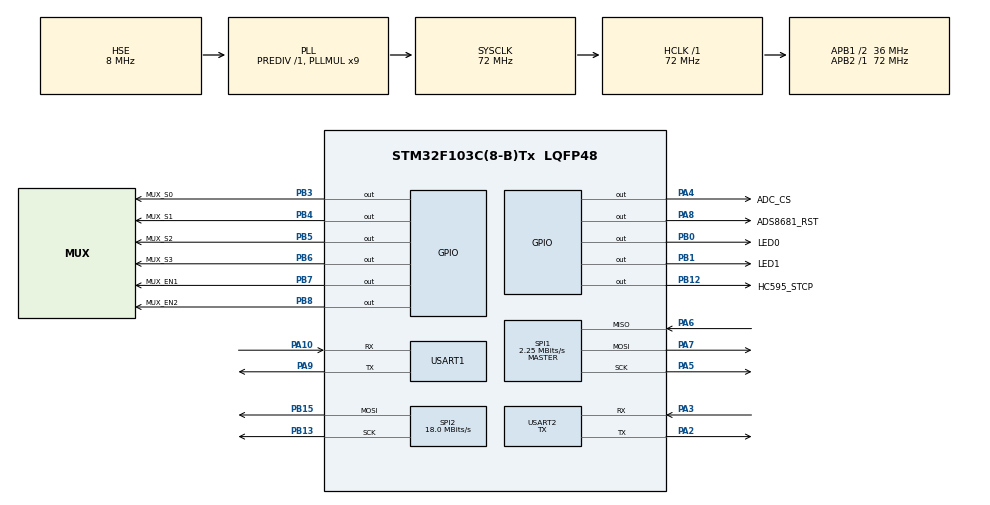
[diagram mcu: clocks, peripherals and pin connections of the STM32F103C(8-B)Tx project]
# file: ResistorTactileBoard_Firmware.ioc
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Dma.Request0=SPI1_RX
Dma.Request1=SPI1_TX
Dma.SPI1_RX.0.Direction=DMA_PERIPH_TO_MEMORY
Dma.SPI1_RX.0.Instance=DMA1_Channel2
Dma.SPI1_RX.0.MemDataAlignment=DMA_MDATAALIGN_BYTE
Dma.SPI1_RX.0.MemInc=DMA_MINC_ENABLE
Dma.SPI1_RX.0.Mode=DMA_NORMAL
Dma.SPI1_RX.0.PeriphDataAlignment=DMA_PDATAALIGN_BYTE
Dma.SPI1_RX.0.PeriphInc=DMA_PINC_DISABLE
Dma.SPI1_RX.0.Priority=DMA_PRIORITY_HIGH
Dma.SPI1_TX.1.Direction=DMA_MEMORY_TO_PERIPH
Dma.SPI1_TX.1.Instance=DMA1_Channel3
Dma.SPI1_TX.1.MemDataAlignment=DMA_MDATAALIGN_BYTE
Dma.SPI1_TX.1.MemInc=DMA_MINC_ENABLE
Dma.SPI1_TX.1.Mode=DMA_NORMAL
Dma.SPI1_TX.1.PeriphDataAlignment=DMA_PDATAALIGN_BYTE
Dma.SPI1_TX.1.PeriphInc=DMA_PINC_DISABLE
Dma.SPI1_TX.1.Priority=DMA_PRIORITY_HIGH
Mcu.Family=STM32F1
Mcu.Name=STM32F103C(8-B)Tx
Mcu.Package=LQFP48
NVIC.DMA1_Channel2_IRQn=true\:0\:0\:false\:false\:true\:false\:true\:true
NVIC.DMA1_Channel3_IRQn=true\:0\:0\:false\:false\:true\:false\:true\:true
NVIC.PriorityGroup=NVIC_PRIORITYGROUP_4
NVIC.TIM2_IRQn=true\:0\:0\:false\:false\:true\:true\:true\:true
PA10.Mode=Asynchronous
PA10.Signal=USART1_RX
PA13.Mode=Serial_Wire
PA13.Signal=SYS_JTMS-SWDIO
PA14.Mode=Serial_Wire
PA14.Signal=SYS_JTCK-SWCLK
PA2.Mode=Asynchronous
PA2.Signal=USART2_TX
PA3.Mode=Asynchronous
PA3.Signal=USART2_RX
PA4.GPIO_Label=ADC_CS
PA4.PinState=GPIO_PIN_SET
PA4.Signal=GPIO_Output
PA5.Mode=Full_Duplex_Master
PA5.Signal=SPI1_SCK
PA6.Mode=Full_Duplex_Master
PA6.Signal=SPI1_MISO
PA7.Mode=Full_Duplex_Master
PA7.Signal=SPI1_MOSI
PA8.GPIO_Label=ADS8681_RST
PA8.Signal=GPIO_Output
PA9.Mode=Asynchronous
PA9.Signal=USART1_TX
PB0.GPIO_Label=LED0
PB0.Signal=GPIO_Output
PB1.GPIO_Label=LED1
PB1.Signal=GPIO_Output
PB12.GPIO_Label=HC595_STCP
PB12.Signal=GPIO_Output
PB13.Mode=TX_Only_Simplex_Unidirect_Master
PB13.Signal=SPI2_SCK
PB15.Mode=TX_Only_Simplex_Unidirect_Master
PB15.Signal=SPI2_MOSI
PB3.GPIO_Label=MUX_S0
PB3.Signal=GPIO_Output
PB4.GPIO_Label=MUX_S1
PB4.Signal=GPIO_Output
PB5.GPIO_Label=MUX_S2
PB5.Signal=GPIO_Output
PB6.GPIO_Label=MUX_S3
PB6.Signal=GPIO_Output
PB7.GPIO_Label=MUX_EN1
PB7.Signal=GPIO_Output
PB8.GPIO_Label=MUX_EN2
PB8.Signal=GPIO_Output
PD0-OSC_IN.Mode=HSE-External-Oscillator
PD0-OSC_IN.Signal=RCC_OSC_IN
PD1-OSC_OUT.Mode=HSE-External-Oscillator
PD1-OSC_OUT.Signal=RCC_OSC_OUT
ProjectManager.HeapSize=0x200
ProjectManager.StackSize=0x400
ProjectManager.TargetToolchain=CMake
RCC.AHBFreq_Value=72000000
RCC.APB1CLKDivider=RCC_HCLK_DIV2
RCC.APB1Freq_Value=36000000
RCC.APB1TimFreq_Value=72000000
RCC.APB2Freq_Value=72000000
RCC.APB2TimFreq_Value=72000000
RCC.HCLKFreq_Value=72000000
RCC.PLLMUL=RCC_PLL_MUL9
RCC.PLLSourceVirtual=RCC_PLLSOURCE_HSE
RCC.SYSCLKFreq_VALUE=72000000
RCC.SYSCLKSource=RCC_SYSCLKSOURCE_PLLCLK
RCC.USBFreq_Value=72000000
SPI1.BaudRatePrescaler=SPI_BAUDRATEPRESCALER_32
SPI1.CalculateBaudRate=2.25 MBits/s
SPI1.Direction=SPI_DIRECTION_2LINES
SPI1.Mode=SPI_MODE_MASTER
SPI1.VirtualType=VM_MASTER
SPI2.CalculateBaudRate=18.0 MBits/s
SPI2.Direction=SPI_DIRECTION_2LINES
SPI2.Mode=SPI_MODE_MASTER
SPI2.VirtualType=VM_MASTER
TIM2.Period=99
TIM2.Prescaler=71
USART1.VirtualMode=VM_ASYNC
USART2.Mode=MODE_TX
USART2.VirtualMode=VM_ASYNC
VP_TIM2_VS_ClockSourceINT.Mode=Internal
board=custom

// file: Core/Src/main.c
/* USER CODE BEGIN Header */
/**
  ******************************************************************************
  * @file           : main.c
  * @brief          : Main program body
  ******************************************************************************
  * @attention
  *
  * Copyright (c) 2026 STMicroelectronics.
  * All rights reserved.
  *
  * This software is licensed under terms that can be found in the LICENSE file
  * in the root directory of this software component.
  * If no LICENSE file comes with this software, it is provided AS-IS.
  *
  ******************************************************************************
  */
/* USER CODE END Header */
#include "main.h"
#include "dma.h"
#include "spi.h"
#include "tim.h"
#include "usart.h"
#include "gpio.h"

/* USER CODE BEGIN Includes */

/* ==========================================================================
 *  Change: 新增
 *  Editor: 谢峰
 *  Time: 2026-09-18
 *  Range: 引入裸机应用编排入口，main不承载业务状态机
 * ========================================================================== */
#include "app_main.h"

/* USER CODE END Includes */

void SystemClock_Config(void);

int main(void)
{

  /* MCU Configuration--------------------------------------------------------*/

  /* Reset of all peripherals, Initializes the Flash interface and the Systick. */
  HAL_Init();

  /* Configure the system clock */
  SystemClock_Config();

  /* Initialize all configured peripherals */
  MX_GPIO_Init();
  MX_DMA_Init();
  MX_SPI1_Init();
  MX_USART1_UART_Init();
  MX_USART2_UART_Init();
  MX_SPI2_Init();
  MX_TIM2_Init();
  /* USER CODE BEGIN 2 */

  /* ==========================================================================
   *  Change: 新增
   *  Editor: 谢峰
   *  Time: 2026-09-18
   *  Range: 外设初始化后启动ADC采集、双缓冲和双串口裸机服务
   * ========================================================================== */
  if (!app_init())
  {
    Error_Handler();
  }

  /* USER CODE END 2 */

  /* Infinite loop */
  /* USER CODE BEGIN WHILE */
  while (1)
  {
    /* ==========================================================================
     *  Change: 新增
     *  Editor: 谢峰
     *  Time: 2026-09-18
     *  Range: 非阻塞超级循环处理命令、扫描事件、打包和USART2发送
     * ========================================================================== */
    app_process();
    /* USER CODE END WHILE */

  }
}

void SystemClock_Config(void)
{
  RCC_OscInitTypeDef RCC_OscInitStruct = {0};
  RCC_ClkInitTypeDef RCC_ClkInitStruct = {0};

  /** Initializes the RCC Oscillators according to the specified parameters
  * in the RCC_OscInitTypeDef structure.
  */
  RCC_OscInitStruct.OscillatorType = RCC_OSCILLATORTYPE_HSE;
  RCC_OscInitStruct.HSEState = RCC_HSE_ON;
  RCC_OscInitStruct.HSEPredivValue = RCC_HSE_PREDIV_DIV1;
  RCC_OscInitStruct.HSIState = RCC_HSI_ON;
  RCC_OscInitStruct.PLL.PLLState = RCC_PLL_ON;
  RCC_OscInitStruct.PLL.PLLSource = RCC_PLLSOURCE_HSE;
  RCC_OscInitStruct.PLL.PLLMUL = RCC_PLL_MUL9;
  if (HAL_RCC_OscConfig(&RCC_OscInitStruct) != HAL_OK)
  {
    Error_Handler();
  }

  /** Initializes the CPU, AHB and APB buses clocks
  */
  RCC_ClkInitStruct.ClockType = RCC_CLOCKTYPE_HCLK|RCC_CLOCKTYPE_SYSCLK
                              |RCC_CLOCKTYPE_PCLK1|RCC_CLOCKTYPE_PCLK2;
  RCC_ClkInitStruct.SYSCLKSource = RCC_SYSCLKSOURCE_PLLCLK;
  RCC_ClkInitStruct.AHBCLKDivider = RCC_SYSCLK_DIV1;
  RCC_ClkInitStruct.APB1CLKDivider = RCC_HCLK_DIV2;
  RCC_ClkInitStruct.APB2CLKDivider = RCC_HCLK_DIV1;

  if (HAL_RCC_ClockConfig(&RCC_ClkInitStruct, FLASH_LATENCY_2) != HAL_OK)
  {
    Error_Handler();
  }
}

void Error_Handler(void)
{
  __disable_irq();
  while (1)
  {
  }
}
